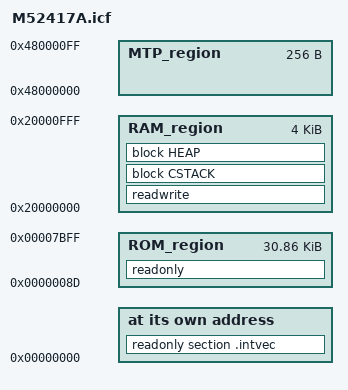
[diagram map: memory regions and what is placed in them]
define symbol __ICFEDIT_intvec_start__     = 0x00000000;
define symbol __ICFEDIT_region_ROM_start__ = 0x0000008D;
define symbol __ICFEDIT_region_ROM_end__   = 0x00007BFF;
define symbol __ICFEDIT_region_RAM_start__ = 0x20000000;
define symbol __ICFEDIT_region_RAM_end__   = 0x20000FFF;
define symbol __ICFEDIT_region_MTP_start__ = 0x48000000;
define symbol __ICFEDIT_region_MTP_end__   = 0x480000FF;

define symbol __ICFEDIT_size_cstack__ = 0x300;
define symbol __ICFEDIT_size_heap__   = 0x0;

define memory mem with size = 4G;

define region ROM_region = mem:[from __ICFEDIT_region_ROM_start__ to __ICFEDIT_region_ROM_end__];
define region RAM_region = mem:[from __ICFEDIT_region_RAM_start__ to __ICFEDIT_region_RAM_end__];
define region MTP_region = mem:[from __ICFEDIT_region_MTP_start__ to __ICFEDIT_region_MTP_end__];

define block CSTACK with alignment = 8, size = __ICFEDIT_size_cstack__   { };
define block HEAP   with alignment = 8, size = __ICFEDIT_size_heap__     { };

initialize by copy { readwrite };
do not initialize  { section .noinit };

place at address mem:__ICFEDIT_intvec_start__ { readonly section .intvec };

place in ROM_region { readonly };
place in RAM_region { readwrite, block CSTACK, block HEAP };

check that size(block CSTACK) >= maxstack("task")
                                +maxstack("sys_state_module_interrupts")
                                +maxstack("system_ctrl_module_interrupts")
                                +maxstack("sw_timer_module_interrupts")
                                +maxstack("dsp_module_interrupts")
                                +maxstack("dsi3_module_interrupts")
                                +50;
